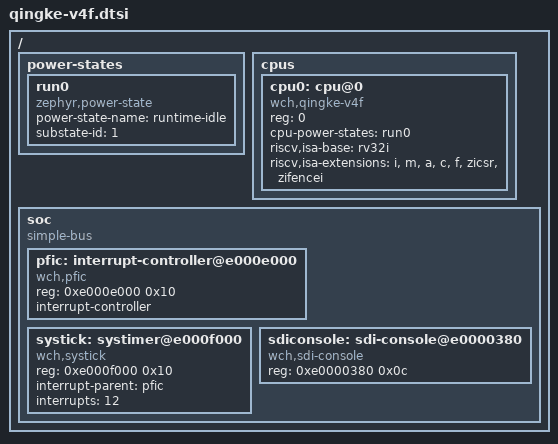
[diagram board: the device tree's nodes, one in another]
/*
 * Copyright (c) 2025 Bootlin
 *
 * SPDX-License-Identifier: Apache-2.0
 */

/ {
	#address-cells = <1>;
	#size-cells = <1>;

	power-states {
		run0: run0 {
			compatible = "zephyr,power-state";
			power-state-name = "runtime-idle";
			substate-id = <1>;
		};
	};

	cpus {
		#address-cells = <1>;
		#size-cells = <0>;

		cpu0: cpu@0 {
			compatible = "wch,qingke-v4f", "riscv";
			reg = <0>;
			device_type = "cpu";
			cpu-power-states = <&run0>;
			riscv,isa-base = "rv32i";
			riscv,isa-extensions = "i", "m", "a", "c", "f", "zicsr", "zifencei";
		};
	};

	soc {
		compatible = "simple-bus";
		ranges;
		#address-cells = <1>;
		#size-cells = <1>;

		pfic: interrupt-controller@e000e000 {
			compatible = "wch,pfic";
			reg = <0xe000e000 0x10>;
			#address-cells = <0>;
			#interrupt-cells = <1>;
			interrupt-controller;
			status = "okay";
		};

		systick: systimer@e000f000 {
			compatible = "wch,systick";
			reg = <0xe000f000 0x10>;
			interrupt-parent = <&pfic>;
			interrupts = <12>;
			status = "okay";
		};

		sdiconsole: sdi-console@e0000380 {
			compatible = "wch,sdi-console";
			reg = <0xe0000380 0x0c>;
		};
	};
};
